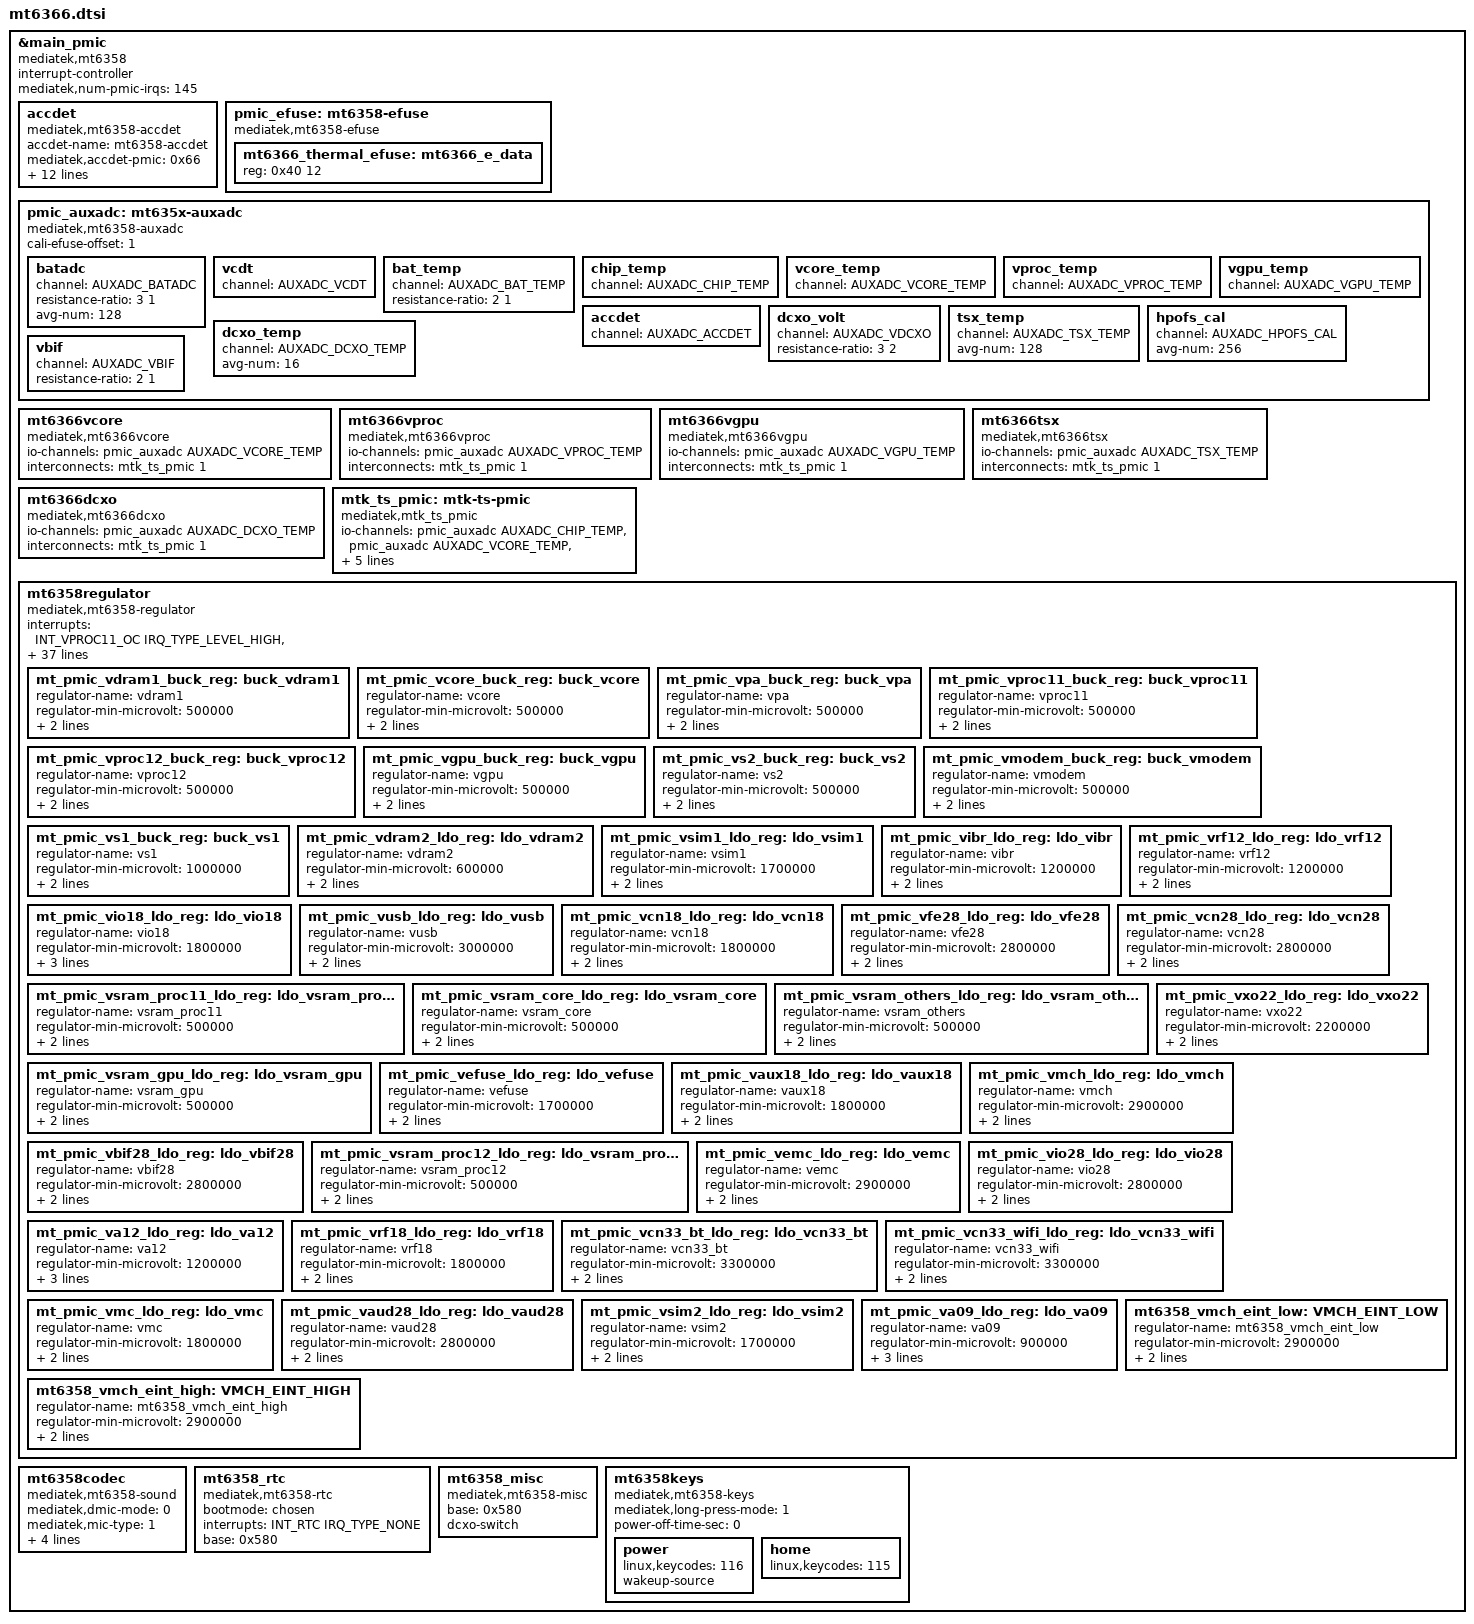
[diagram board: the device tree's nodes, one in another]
/* SPDX-License-Identifier: GPL-2.0 */
/*
 * Copyright (c) 2021 MediaTek Inc.
*/
&main_pmic {
	compatible = "mediatek,mt6358";
	interrupt-controller;
	#interrupt-cells = <2>;
	mediatek,num-pmic-irqs = <145>;

	accdet: accdet {
		compatible = "mediatek,mt6358-accdet";
		accdet-name = "mt6358-accdet";
		mediatek,accdet-pmic = <0x66>;
		/* accdet micbias voltage: 0x07,2.7v;0x05,2.5v;0x02,1.9v */
		accdet-mic-vol = <6>;
		headset-mode-setting = <0x500 0x500 1 0x1f0
					0x800 0x800 0x20 0x44
					0x00 0x00
					0xe 0x00 0x00 0x00 0x00>;
		accdet-plugout-debounce = <1>;
		/*1:ACC mode, 2:low cost without in bias, 6:low cost with in bias*/
		accdet-mic-mode = <1>;
		/* eint_level_trigger: 8,LEVEL_LOW(DEF) ;4,LV_HIGH;others,LV_LOW */
		headset-eint-level-pol = <8>;
		/*0--MD_MAX--UP_MAX--DW_MAX*/
		headset-three-key-threshold = <0 80 220 400>;
		headset-three-key-threshold-CDD = <0 121 192 600>;
		/*0--MD_MAX--VOICE_MAX--UP_MAX--DW_MAX*/
		headset-four-key-threshold = <0 58 121 192 400>;
		io-channels = <&pmic_auxadc AUXADC_ACCDET>;
		io-channel-names = "pmic_accdet";
		nvmem = <&pmic_efuse>;
		nvmem-names = "mt63xx-accdet-efuse";
		status = "okay";
	};

	pmic_efuse: mt6358-efuse {
			compatible = "mediatek,mt6358-efuse";
			#address-cells = <1>;
			#size-cells = <1>;
			mt6366_thermal_efuse: mt6366_e_data {
				reg = <0x40 12>;
			};
		};

	pmic_auxadc: mt635x-auxadc {
		compatible = "mediatek,mt6358-auxadc";
		#io-channel-cells = <1>;
		/* efuse offset from mt6358 */
		cali-efuse-offset = <1>;
		batadc {
			channel = <AUXADC_BATADC>;
			resistance-ratio = <3 1>;
			avg-num = <128>;
		};
		vcdt {
			channel = <AUXADC_VCDT>;
		};
		bat_temp {
			channel = <AUXADC_BAT_TEMP>;
			resistance-ratio = <2 1>;
		};
		chip_temp {
			channel = <AUXADC_CHIP_TEMP>;
		};
		vcore_temp {
			channel = <AUXADC_VCORE_TEMP>;
		};
		vproc_temp {
			channel = <AUXADC_VPROC_TEMP>;
		};
		vgpu_temp {
			channel = <AUXADC_VGPU_TEMP>;
		};
		accdet {
			channel = <AUXADC_ACCDET>;
		};
		dcxo_volt {
			channel = <AUXADC_VDCXO>;
			resistance-ratio = <3 2>;
		};
		tsx_temp {
			channel = <AUXADC_TSX_TEMP>;
			avg-num = <128>;
		};
		hpofs_cal {
			channel = <AUXADC_HPOFS_CAL>;
			avg-num = <256>;
		};
		dcxo_temp {
			channel = <AUXADC_DCXO_TEMP>;
			avg-num = <16>;
		};
		vbif {
			channel = <AUXADC_VBIF>;
			resistance-ratio = <2 1>;
		};
	};


	mt6366vcore: mt6366vcore {
		compatible = "mediatek,mt6366vcore";
		io-channels =
			<&pmic_auxadc AUXADC_VCORE_TEMP>;
		io-channel-names =
			"pmic_buck1_temp";
		interconnects = <&mtk_ts_pmic 1>;
	};

	mt6366vproc: mt6366vproc {
		compatible = "mediatek,mt6366vproc";
		io-channels =
			<&pmic_auxadc AUXADC_VPROC_TEMP>;
		io-channel-names =
			"pmic_buck2_temp";
		interconnects = <&mtk_ts_pmic 1>;
};

	mt6366vgpu: mt6366vgpu {
		compatible = "mediatek,mt6366vgpu";
		io-channels =
			<&pmic_auxadc AUXADC_VGPU_TEMP>;
		io-channel-names =
			"pmic_buck3_temp";
		interconnects = <&mtk_ts_pmic 1>;
	};

	mt6366tsx: mt6366tsx {
		compatible = "mediatek,mt6366tsx";
		io-channels =
			<&pmic_auxadc AUXADC_TSX_TEMP>;
		io-channel-names =
			"pmic_tsx_temp";
		interconnects = <&mtk_ts_pmic 1>;
	};

	mt6366dcxo: mt6366dcxo {
		compatible = "mediatek,mt6366dcxo";
		io-channels =
			<&pmic_auxadc AUXADC_DCXO_TEMP>;
		io-channel-names =
			"pmic_dcxo_temp";
		interconnects = <&mtk_ts_pmic 1>;
	};

	mtk_ts_pmic: mtk-ts-pmic {
		compatible = "mediatek,mtk_ts_pmic";
		io-channels =
			<&pmic_auxadc AUXADC_CHIP_TEMP>,
			<&pmic_auxadc AUXADC_VCORE_TEMP>,
			<&pmic_auxadc AUXADC_VPROC_TEMP>,
			<&pmic_auxadc AUXADC_VGPU_TEMP>,
			<&pmic_auxadc AUXADC_TSX_TEMP>,
			<&pmic_auxadc AUXADC_DCXO_TEMP>;
		io-channel-names =
			"pmic_chip_temp",
			"pmic_buck1_temp",
			"pmic_buck2_temp",
			"pmic_buck3_temp",
			"pmic_tsx_temp",
			"pmic_dcxo_temp";
		interconnects = <&pmic_auxadc 1>;
		#interconnect-cells = <1>;
	};

	mt6358regulator: mt6358regulator {
		compatible = "mediatek,mt6358-regulator";
		interrupts =
			<INT_VPROC11_OC IRQ_TYPE_LEVEL_HIGH>,
			<INT_VPROC12_OC IRQ_TYPE_LEVEL_HIGH>,
			<INT_VCORE_OC IRQ_TYPE_LEVEL_HIGH>,
			<INT_VGPU_OC IRQ_TYPE_LEVEL_HIGH>,
			<INT_VMODEM_OC IRQ_TYPE_LEVEL_HIGH>,
			<INT_VDRAM1_OC IRQ_TYPE_LEVEL_HIGH>,
			<INT_VS1_OC IRQ_TYPE_LEVEL_HIGH>,
			<INT_VS2_OC IRQ_TYPE_LEVEL_HIGH>,
			<INT_VPA_OC IRQ_TYPE_LEVEL_HIGH>,
			<INT_VFE28_OC IRQ_TYPE_LEVEL_HIGH>,
			<INT_VXO22_OC IRQ_TYPE_LEVEL_HIGH>,
			<INT_VRF18_OC IRQ_TYPE_LEVEL_HIGH>,
			<INT_VRF12_OC IRQ_TYPE_LEVEL_HIGH>,
			<INT_VEFUSE_OC IRQ_TYPE_LEVEL_HIGH>,
			<INT_VCN33_OC IRQ_TYPE_LEVEL_HIGH>,
			<INT_VCN28_OC IRQ_TYPE_LEVEL_HIGH>,
			<INT_VCN18_OC IRQ_TYPE_LEVEL_HIGH>,
			<INT_VM18_OC IRQ_TYPE_LEVEL_HIGH>,
			<INT_VMDDR_OC IRQ_TYPE_LEVEL_HIGH>,
			<INT_VSRAM_CORE_OC IRQ_TYPE_LEVEL_HIGH>,
			<INT_VA12_OC IRQ_TYPE_LEVEL_HIGH>,
			<INT_VAUX18_OC IRQ_TYPE_LEVEL_HIGH>,
			<INT_VAUD28_OC IRQ_TYPE_LEVEL_HIGH>,
			<INT_VIO28_OC IRQ_TYPE_LEVEL_HIGH>,
			<INT_VIO18_OC IRQ_TYPE_LEVEL_HIGH>,
			<INT_VSRAM_PROC11_OC IRQ_TYPE_LEVEL_HIGH>,
			<INT_VSRAM_PROC12_OC IRQ_TYPE_LEVEL_HIGH>,
			<INT_VSRAM_OTHERS_OC IRQ_TYPE_LEVEL_HIGH>,
			<INT_VSRAM_GPU_OC IRQ_TYPE_LEVEL_HIGH>,
			<INT_VDRAM2_OC IRQ_TYPE_LEVEL_HIGH>,
			<INT_VMC_OC IRQ_TYPE_LEVEL_HIGH>,
			<INT_VMCH_OC IRQ_TYPE_LEVEL_HIGH>,
			<INT_VEMC_OC IRQ_TYPE_LEVEL_HIGH>,
			<INT_VSIM1_OC IRQ_TYPE_LEVEL_HIGH>,
			<INT_VSIM2_OC IRQ_TYPE_LEVEL_HIGH>,
			<INT_VIBR_OC IRQ_TYPE_LEVEL_HIGH>,
			<INT_VUSB_OC IRQ_TYPE_LEVEL_HIGH>,
			<INT_VBIF28_OC IRQ_TYPE_LEVEL_HIGH>;
		interrupt-names =
			"VPROC11",
			"VPROC12",
			"VCORE",
			"VGPU",
			"VMODEM",
			"VDRAM1",
			"VS1",
			"VS2",
			"VPA",
			"VFE28",
			"VXO22",
			"VRF18",
			"VRF12",
			"VEFUSE",
			"VCN33_BT",
			"VCN28",
			"VCN18",
			"VM18",
			"VMDDR",
			"VSRAM_CORE",
			"VA12",
			"VAUX18",
			"VAUD28",
			"VIO28",
			"VIO18",
			"VSRAM_PROC11",
			"VSRAM_PROC12",
			"VSRAM_OTHERS",
			"VSRAM_GPU",
			"VDRAM2",
			"VMC",
			"VMCH",
			"VEMC",
			"VSIM1",
			"VSIM2",
			"VIBR",
			"VUSB",
			"VBIF28";
		mt_pmic_vdram1_buck_reg: buck_vdram1 {
			regulator-name = "vdram1";
			regulator-min-microvolt = <500000>;
			regulator-max-microvolt = <2087500>;
			regulator-enable-ramp-delay = <0>;
		};
		mt_pmic_vcore_buck_reg: buck_vcore {
			regulator-name = "vcore";
			regulator-min-microvolt = <500000>;
			regulator-max-microvolt = <1293750>;
			regulator-enable-ramp-delay = <200>;
		};
		mt_pmic_vpa_buck_reg: buck_vpa {
			regulator-name = "vpa";
			regulator-min-microvolt = <500000>;
			regulator-max-microvolt = <3650000>;
			regulator-enable-ramp-delay = <250>;
		};
		mt_pmic_vproc11_buck_reg: buck_vproc11 {
			regulator-name = "vproc11";
			regulator-min-microvolt = <500000>;
			regulator-max-microvolt = <1293750>;
			regulator-enable-ramp-delay = <200>;
		};
		mt_pmic_vproc12_buck_reg: buck_vproc12 {
			regulator-name = "vproc12";
			regulator-min-microvolt = <500000>;
			regulator-max-microvolt = <1293750>;
			regulator-enable-ramp-delay = <200>;
		};
		mt_pmic_vgpu_buck_reg: buck_vgpu {
			regulator-name = "vgpu";
			regulator-min-microvolt = <500000>;
			regulator-max-microvolt = <1293750>;
			regulator-enable-ramp-delay = <200>;
		};
		mt_pmic_vs2_buck_reg: buck_vs2 {
			regulator-name = "vs2";
			regulator-min-microvolt = <500000>;
			regulator-max-microvolt = <2087500>;
			regulator-enable-ramp-delay = <0>;
		};
		mt_pmic_vmodem_buck_reg: buck_vmodem {
			regulator-name = "vmodem";
			regulator-min-microvolt = <500000>;
			regulator-max-microvolt = <1293750>;
			regulator-enable-ramp-delay = <900>;
		};
		mt_pmic_vs1_buck_reg: buck_vs1 {
			regulator-name = "vs1";
			regulator-min-microvolt = <1000000>;
			regulator-max-microvolt = <2587500>;
			regulator-enable-ramp-delay = <0>;
		};
		mt_pmic_vdram2_ldo_reg: ldo_vdram2 {
			regulator-name = "vdram2";
			regulator-min-microvolt = <600000>;
			regulator-max-microvolt = <1800000>;
			regulator-enable-ramp-delay = <3300>;
		};
		mt_pmic_vsim1_ldo_reg: ldo_vsim1 {
			regulator-name = "vsim1";
			regulator-min-microvolt = <1700000>;
			regulator-max-microvolt = <3100000>;
			regulator-enable-ramp-delay = <540>;
		};
		mt_pmic_vibr_ldo_reg: ldo_vibr {
			regulator-name = "vibr";
			regulator-min-microvolt = <1200000>;
			regulator-max-microvolt = <3300000>;
			regulator-enable-ramp-delay = <60>;
		};
		mt_pmic_vrf12_ldo_reg: ldo_vrf12 {
			regulator-name = "vrf12";
			regulator-min-microvolt = <1200000>;
			regulator-max-microvolt = <1200000>;
			regulator-enable-ramp-delay = <120>;
		};
		mt_pmic_vio18_ldo_reg: ldo_vio18 {
			regulator-name = "vio18";
			regulator-min-microvolt = <1800000>;
			regulator-max-microvolt = <1800000>;
			regulator-enable-ramp-delay = <2700>;
			regulator-always-on;
		};
		mt_pmic_vusb_ldo_reg: ldo_vusb {
			regulator-name = "vusb";
			regulator-min-microvolt = <3000000>;
			regulator-max-microvolt = <3100000>;
			regulator-enable-ramp-delay = <270>;
		};
		mt_pmic_vcn18_ldo_reg: ldo_vcn18 {
			regulator-name = "vcn18";
			regulator-min-microvolt = <1800000>;
			regulator-max-microvolt = <1800000>;
			regulator-enable-ramp-delay = <270>;
		};
		mt_pmic_vfe28_ldo_reg: ldo_vfe28 {
			regulator-name = "vfe28";
			regulator-min-microvolt = <2800000>;
			regulator-max-microvolt = <2800000>;
			regulator-enable-ramp-delay = <270>;
		};
		mt_pmic_vsram_proc11_ldo_reg: ldo_vsram_proc11 {
			regulator-name = "vsram_proc11";
			regulator-min-microvolt = <500000>;
			regulator-max-microvolt = <1293750>;
			regulator-enable-ramp-delay = <240>;
		};
		mt_pmic_vcn28_ldo_reg: ldo_vcn28 {
			regulator-name = "vcn28";
			regulator-min-microvolt = <2800000>;
			regulator-max-microvolt = <2800000>;
			regulator-enable-ramp-delay = <270>;
		};
		mt_pmic_vsram_core_ldo_reg: ldo_vsram_core {
			regulator-name = "vsram_core";
			regulator-min-microvolt = <500000>;
			regulator-max-microvolt = <1293750>;
			regulator-enable-ramp-delay = <240>;
		};
		mt_pmic_vsram_others_ldo_reg: ldo_vsram_others {
			regulator-name = "vsram_others";
			regulator-min-microvolt = <500000>;
			regulator-max-microvolt = <1293750>;
			regulator-enable-ramp-delay = <240>;
		};
		mt_pmic_vsram_gpu_ldo_reg: ldo_vsram_gpu {
			regulator-name = "vsram_gpu";
			regulator-min-microvolt = <500000>;
			regulator-max-microvolt = <1293750>;
			regulator-enable-ramp-delay = <240>;
		};
		mt_pmic_vxo22_ldo_reg: ldo_vxo22 {
			regulator-name = "vxo22";
			regulator-min-microvolt = <2200000>;
			regulator-max-microvolt = <2200000>;
			regulator-enable-ramp-delay = <120>;
		};
		mt_pmic_vefuse_ldo_reg: ldo_vefuse {
			regulator-name = "vefuse";
			regulator-min-microvolt = <1700000>;
			regulator-max-microvolt = <1900000>;
			regulator-enable-ramp-delay = <270>;
		};
		mt_pmic_vaux18_ldo_reg: ldo_vaux18 {
			regulator-name = "vaux18";
			regulator-min-microvolt = <1800000>;
			regulator-max-microvolt = <1800000>;
			regulator-enable-ramp-delay = <270>;
		};
		mt_pmic_vmch_ldo_reg: ldo_vmch {
			regulator-name = "vmch";
			regulator-min-microvolt = <2900000>;
			regulator-max-microvolt = <3300000>;
			regulator-enable-ramp-delay = <60>;
		};
		mt_pmic_vbif28_ldo_reg: ldo_vbif28 {
			regulator-name = "vbif28";
			regulator-min-microvolt = <2800000>;
			regulator-max-microvolt = <2800000>;
			regulator-enable-ramp-delay = <270>;
		};
		mt_pmic_vsram_proc12_ldo_reg: ldo_vsram_proc12 {
			regulator-name = "vsram_proc12";
			regulator-min-microvolt = <500000>;
			regulator-max-microvolt = <1293750>;
			regulator-enable-ramp-delay = <240>;
		};
		mt_pmic_vemc_ldo_reg: ldo_vemc {
			regulator-name = "vemc";
			regulator-min-microvolt = <2900000>;
			regulator-max-microvolt = <3300000>;
			regulator-enable-ramp-delay = <60>;
		};
		mt_pmic_vio28_ldo_reg: ldo_vio28 {
			regulator-name = "vio28";
			regulator-min-microvolt = <2800000>;
			regulator-max-microvolt = <2800000>;
			regulator-enable-ramp-delay = <270>;
		};
		mt_pmic_va12_ldo_reg: ldo_va12 {
			regulator-name = "va12";
			regulator-min-microvolt = <1200000>;
			regulator-max-microvolt = <1200000>;
			regulator-enable-ramp-delay = <270>;
			regulator-always-on;
		};
		mt_pmic_vrf18_ldo_reg: ldo_vrf18 {
			regulator-name = "vrf18";
			regulator-min-microvolt = <1800000>;
			regulator-max-microvolt = <1800000>;
			regulator-enable-ramp-delay = <120>;
		};
		mt_pmic_vcn33_bt_ldo_reg: ldo_vcn33_bt {
			regulator-name = "vcn33_bt";
			regulator-min-microvolt = <3300000>;
			regulator-max-microvolt = <3500000>;
			regulator-enable-ramp-delay = <270>;
		};
		mt_pmic_vcn33_wifi_ldo_reg: ldo_vcn33_wifi {
			regulator-name = "vcn33_wifi";
			regulator-min-microvolt = <3300000>;
			regulator-max-microvolt = <3500000>;
			regulator-enable-ramp-delay = <270>;
		};
		mt_pmic_vmc_ldo_reg: ldo_vmc {
			regulator-name = "vmc";
			regulator-min-microvolt = <1800000>;
			regulator-max-microvolt = <3300000>;
			regulator-enable-ramp-delay = <60>;
		};
		mt_pmic_vaud28_ldo_reg: ldo_vaud28 {
			regulator-name = "vaud28";
			regulator-min-microvolt = <2800000>;
			regulator-max-microvolt = <2800000>;
			regulator-enable-ramp-delay = <270>;
		};
		mt_pmic_vsim2_ldo_reg: ldo_vsim2 {
			regulator-name = "vsim2";
			regulator-min-microvolt = <1700000>;
			regulator-max-microvolt = <3100000>;
			regulator-enable-ramp-delay = <540>;
		};
		mt_pmic_va09_ldo_reg: ldo_va09 {
			regulator-name = "va09";
			regulator-min-microvolt = <900000>;
			regulator-max-microvolt = <900000>;
			regulator-enable-ramp-delay = <264>;
			regulator-boot-on;
		};
		mt6358_vmch_eint_high: VMCH_EINT_HIGH {
				regulator-name = "mt6358_vmch_eint_high";
				regulator-min-microvolt = <2900000>;
				regulator-max-microvolt = <3300000>;
				regulator-enable-ramp-delay = <60>;
		};
		mt6358_vmch_eint_low: VMCH_EINT_LOW {
				regulator-name = "mt6358_vmch_eint_low";
				regulator-min-microvolt = <2900000>;
				regulator-max-microvolt = <3300000>;
				regulator-enable-ramp-delay = <60>;
		};
	};	/* End of mt6358regulator */
	mt6358codec: mt6358codec {
			compatible = "mediatek,mt6358-sound";
			mediatek,dmic-mode = <0>;
			mediatek,mic-type = <1>;
			io-channels = <&pmic_auxadc AUXADC_HPOFS_CAL>;
			io-channel-names = "pmic_hpofs_cal";
			nvmem = <&pmic_efuse>;
			nvmem-names = "pmic-hp-efuse";
			reg-vaud28-supply = <&mt_pmic_vaud28_ldo_reg>;
		};
	mt6358_rtc: mt6358_rtc {
		compatible = "mediatek,mt6358-rtc";
		bootmode = <&chosen>;
		interrupts = <INT_RTC IRQ_TYPE_NONE>;
		interrupt-names = "rtc";
		base = <0x580>;
	};
	mt6358_misc: mt6358_misc {
		compatible = "mediatek,mt6358-misc";
		base = <0x580>;
		dcxo-switch;
	};
	mt6358keys: mt6358keys {
		compatible = "mediatek,mt6358-keys";
		mediatek,long-press-mode = <1>;
		power-off-time-sec = <0>;
		power {
			linux,keycodes = <116>;
			wakeup-source;
		};
		home {
			linux,keycodes = <115>;
		};
	};
};/* End of main_pmic */
